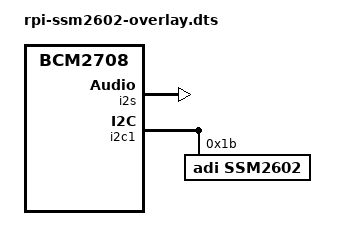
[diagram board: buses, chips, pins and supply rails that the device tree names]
// Definitions for SSM2602
/dts-v1/;
/plugin/;

/ {
    compatible = "brcm,bcm2708";

    fragment@0 {
        target = <&i2s>;
        __overlay__ {
            status = "okay";
        };
    };

    fragment@1 {
        target = <&i2c1>;
        __overlay__ {
            #address-cells = <1>;
            #size-cells = <0>;
            status = "okay";

            ssm2602@1b {
                #sound-dai-cells = <0>;
                compatible = "adi,ssm2602";
                reg = <0x1b>;
                status = "okay";
            };
        };
    };

    fragment@2 {
        target = <&sound>;
        __overlay__ {
            compatible = "adi,rpi-ssm2602";
            i2s-controller = <&i2s>;
            status = "okay";
        };
    };
};
